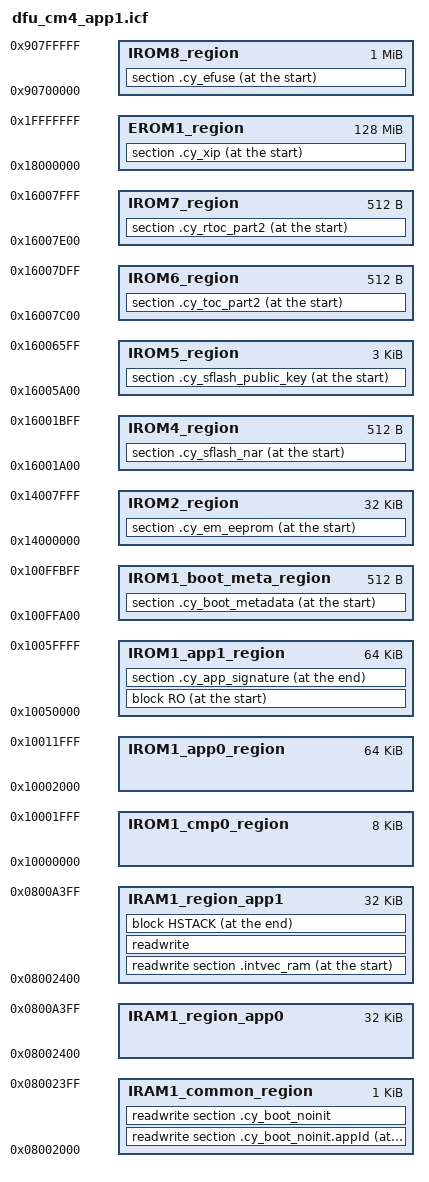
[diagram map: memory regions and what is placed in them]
/***************************************************************************//**
* \file dfu_cm4_app1.icf
* \version 5.2
*
* The linker file for the GNU C compiler.
* Used for the DFU SDK application 1 firmware project.
* Contains only CM4 sections (no section for the CM0p image that
* starts CM4 application 0). Application 1 is uploaded through
* Bootloader Host Tool using the generated cyadc2 file.
*
* \note
* This linker file is generic and handles common use cases. Your project may not
* use each section defined in the linker file and then you may see warnings
* during the build process. Simply comment out or remove the relevant code
* in the linker file.
*
********************************************************************************
* \copyright
* (c) (2016-2024), Cypress Semiconductor Corporation (an Infineon company) or
* an affiliate of Cypress Semiconductor Corporation. All rights reserved.
********************************************************************************
* This software, including source code, documentation and related materials
* ("Software") is owned by Cypress Semiconductor Corporation or one of its
* affiliates ("Cypress") and is protected by and subject to worldwide patent
* protection (United States and foreign), United States copyright laws and
* international treaty provisions. Therefore, you may use this Software only
* as provided in the license agreement accompanying the software package from
* which you obtained this Software ("EULA").
*
* If no EULA applies, Cypress hereby grants you a personal, non-exclusive,
* non-transferable license to copy, modify, and compile the Software source
* code solely for use in connection with Cypress's integrated circuit products.
* Any reproduction, modification, translation, compilation, or representation
* of this Software except as specified above is prohibited without the express
* written permission of Cypress.
*
* Disclaimer: THIS SOFTWARE IS PROVIDED AS-IS, WITH NO WARRANTY OF ANY KIND,
* EXPRESS OR IMPLIED, INCLUDING, BUT NOT LIMITED TO, NONINFRINGEMENT, IMPLIED
* WARRANTIES OF MERCHANTABILITY AND FITNESS FOR A PARTICULAR PURPOSE. Cypress
* reserves the right to make changes to the Software without notice. Cypress
* does not assume any liability arising out of the application or use of the
* Software or any product or circuit described in the Software. Cypress does
* not authorize its products for use in any products where a malfunction or
* failure of the Cypress product may reasonably be expected to result in
* significant property damage, injury or death ("High Risk Product"). By
* including Cypress's product in a High Risk Product, the manufacturer of such
* system or application assumes all risk of such use and in doing so agrees to
* indemnify Cypress against all liability.
*******************************************************************************/

/*###ICF### Section handled by ICF editor, don't touch! ****/
/*-Editor annotation file-*/
/* IcfEditorFile="$TOOLKIT_DIR$\config\ide\IcfEditor\cortex_v1_4.xml" */
/*-Specials-*/
define symbol __ICFEDIT_intvec_start__ = 0x00000000;

/* The symbols below define the location and size of blocks of memory in the target.
 * Use these symbols to specify the memory regions available for allocation.
 */

/* The following symbols control RAM and flash memory allocation for the CM4 core.
 * You can change the memory allocation by editing RAM and flash symbols.
 * Note that 2 KB of RAM (at the end of the SRAM) are reserved for system use.
 * Using this memory region for other purposes will lead to unexpected behavior.
 * Your changes must be aligned with the corresponding symbols for CM0+ core in 'xx_cm0plus.icf',
 * where 'xx' is the device group; for example, 'cy8c6xx7_cm0plus.icf'.
 */
/* RAM */
define symbol __ICFEDIT_region_IRAM1_comon_start__ = 0x08002000;
define symbol __ICFEDIT_region_IRAM1_comon_end__   = 0x080023FF;

define symbol __ICFEDIT_region_IRAM1_app0_start__ = 0x08002400;
define symbol __ICFEDIT_region_IRAM1_app0_end__   = 0x0800A3FF;

define symbol __ICFEDIT_region_IRAM1_app1_start__ = 0x08002400;
define symbol __ICFEDIT_region_IRAM1_app1_end__   = 0x0800A3FF;

/* Flash */
define symbol __ICFEDIT_region_IROM1_cm0p_start__ = 0x10000000;
define symbol __ICFEDIT_region_IROM1_cm0p_end__   = 0x10001FFF;

define symbol __ICFEDIT_region_IROM1_app0_start__ = 0x10002000;
define symbol __ICFEDIT_region_IROM1_app0_end__   = 0x10011FFF;

define symbol __ICFEDIT_region_IROM1_app1_start__ = 0x10050000;
define symbol __ICFEDIT_region_IROM1_app1_end__   = 0x1005FFFF;

/* The region for DFU SDK metadata when it is outside of any application */
define symbol __ICFEDIT_region_IROM1_boot_meta_start__ = 0x100FFA00;
define symbol __ICFEDIT_region_IROM1_boot_meta_end__   = 0x100FFBFF;

/* The following symbols define a 32K flash region used for EEPROM emulation.
 * This region can also be used as the general purpose flash.
 * You can assign sections to this memory region for only one of the cores.
 * Note some middleware (e.g. BLE, Emulated EEPROM) can place their data into this memory region.
 * Therefore, repurposing this memory region will prevent such middleware from operation.
 */
define symbol __ICFEDIT_region_IROM2_start__ = 0x14000000;
define symbol __ICFEDIT_region_IROM2_end__   = 0x14007FFF;

/* The following symbols define device specific memory regions and must not be changed. */
/* Supervisory flash - User Data */
define symbol __ICFEDIT_region_IROM3_start__ = 0x16000800;
define symbol __ICFEDIT_region_IROM3_end__   = 0x160007FF;

/* Supervisory flash - Normal Access Restrictions (NAR) */
define symbol __ICFEDIT_region_IROM4_start__ = 0x16001A00;
define symbol __ICFEDIT_region_IROM4_end__   = 0x16001BFF;

/* Supervisory flash - Public Key */
define symbol __ICFEDIT_region_IROM5_start__ = 0x16005A00;
define symbol __ICFEDIT_region_IROM5_end__   = 0x160065FF;

/* Supervisory flash - Table of Content # 2 */
define symbol __ICFEDIT_region_IROM6_start__ = 0x16007C00;
define symbol __ICFEDIT_region_IROM6_end__   = 0x16007DFF;

/* Supervisory flash - Table of Content # 2 Copy */
define symbol __ICFEDIT_region_IROM7_start__ = 0x16007E00;
define symbol __ICFEDIT_region_IROM7_end__   = 0x16007FFF;

/* eFuse */
define symbol __ICFEDIT_region_IROM8_start__ = 0x90700000;
define symbol __ICFEDIT_region_IROM8_end__   = 0x907FFFFF;

/* XIP */
define symbol __ICFEDIT_region_EROM1_start__ = 0x18000000;
define symbol __ICFEDIT_region_EROM1_end__   = 0x1FFFFFFF;

/*-Sizes-*/
if (!isdefinedsymbol(__STACK_SIZE)) {
  define symbol __ICFEDIT_size_cstack__ = 0x1000;
} else {
  define symbol __ICFEDIT_size_cstack__ = __STACK_SIZE;
}
define symbol __ICFEDIT_size_proc_stack__ = 0x0;

/* Defines the minimum heap size. The actual heap size will be expanded to the end of the stack region */
if (!isdefinedsymbol(__HEAP_SIZE)) {
    define symbol __ICFEDIT_size_heap__ = 0x0400;
} else {
  define symbol __ICFEDIT_size_heap__ = __HEAP_SIZE;
}
/**** End of ICF editor section. ###ICF###*/

/* Size of the Cortex-M0+ application image */
define symbol FLASH_CM0P_SIZE  = 0x2000;

define memory mem with size = 4G;
define region IROM1_cmp0_region = mem:[from __ICFEDIT_region_IROM1_cm0p_start__ to __ICFEDIT_region_IROM1_cm0p_end__];
define region IROM1_app0_region = mem:[from __ICFEDIT_region_IROM1_app0_start__ to __ICFEDIT_region_IROM1_app0_end__];
define region IROM1_app1_region = mem:[from __ICFEDIT_region_IROM1_app1_start__ to __ICFEDIT_region_IROM1_app1_end__];
define region IROM1_boot_meta_region  = mem:[from __ICFEDIT_region_IROM1_boot_meta_start__ to __ICFEDIT_region_IROM1_boot_meta_end__];
define region IROM2_region = mem:[from __ICFEDIT_region_IROM2_start__ to __ICFEDIT_region_IROM2_end__];
define region IROM3_region = mem:[from __ICFEDIT_region_IROM3_start__ to __ICFEDIT_region_IROM3_end__];
define region IROM4_region = mem:[from __ICFEDIT_region_IROM4_start__ to __ICFEDIT_region_IROM4_end__];
define region IROM5_region = mem:[from __ICFEDIT_region_IROM5_start__ to __ICFEDIT_region_IROM5_end__];
define region IROM6_region = mem:[from __ICFEDIT_region_IROM6_start__ to __ICFEDIT_region_IROM6_end__];
define region IROM7_region = mem:[from __ICFEDIT_region_IROM7_start__ to __ICFEDIT_region_IROM7_end__];
define region IROM8_region = mem:[from __ICFEDIT_region_IROM8_start__ to __ICFEDIT_region_IROM8_end__];
define region EROM1_region = mem:[from __ICFEDIT_region_EROM1_start__ to __ICFEDIT_region_EROM1_end__];
define region IRAM1_common_region = mem:[from __ICFEDIT_region_IRAM1_comon_start__ to __ICFEDIT_region_IRAM1_comon_end__];
define region IRAM1_region_app0   = mem:[from __ICFEDIT_region_IRAM1_app0_start__  to __ICFEDIT_region_IRAM1_app0_end__];
define region IRAM1_region_app1   = mem:[from __ICFEDIT_region_IRAM1_app1_start__  to __ICFEDIT_region_IRAM1_app1_end__];

define block CSTACK     with alignment = 8, size = __ICFEDIT_size_cstack__     { };
define block PROC_STACK with alignment = 8, size = __ICFEDIT_size_proc_stack__ { };
define block HEAP       with expanding size, alignment = 8, minimum size = __ICFEDIT_size_heap__ { };
define block HSTACK {block HEAP, block PROC_STACK, last block CSTACK};
define block RO     {first section .intvec, readonly};

/*-Initializations-*/
initialize by copy { readwrite };
do not initialize  { section .noinit, section .intvec_ram,
                     section .cy_boot_noinit.appId, section .cy_boot_noinit };

/*-Placement-*/

/* Flash - Cortex-M4 application image */
place at start of IROM1_app1_region  { block RO };
".cy_app_signature": place at end of IROM1_app1_region { section .cy_app_signature };

/* Emulated EEPROM flash area */
".cy_em_eeprom" : place at start of IROM2_region  { section .cy_em_eeprom };

/* Supervisory flash - User Data */
".cy_sflash_user_data" : place at start of IROM3_region  { section .cy_sflash_user_data };

/* Supervisory flash - NAR */
".cy_sflash_nar" : place at start of IROM4_region  { section .cy_sflash_nar };

/* Supervisory flash - Public Key */
".cy_sflash_public_key" : place at start of IROM5_region  { section .cy_sflash_public_key };

/* Supervisory flash - TOC2 */
".cy_toc_part2" : place at start of IROM6_region  { section .cy_toc_part2 };

/* Supervisory flash - RTOC2 */
".cy_rtoc_part2" : place at start of IROM7_region  { section .cy_rtoc_part2 };

/* eFuse */
".cy_efuse" : place at start of IROM8_region  { section .cy_efuse };

/* Execute in Place (XIP). See the smif driver documentation for details. */
".cy_xip" : place at start of EROM1_region  { section .cy_xip };

/* RAM */
place at start of IRAM1_common_region   { readwrite section .cy_boot_noinit.appId };
place in          IRAM1_common_region   { readwrite section .cy_boot_noinit };
place at start of IRAM1_region_app1  { readwrite section .intvec_ram};
place in          IRAM1_region_app1  { readwrite };
place at end   of IRAM1_region_app1  { block HSTACK };

/* These sections are used for additional metadata (silicon revision, Silicon/JTAG ID, etc.) storage. */
".cymeta" : place at address mem : 0x90500000 { readonly section .cymeta };

/* App0 uses it to initialize DFU SDK metadata, in the dfu_user.c file */
".cy_boot_metadata" : place at start of IROM1_boot_meta_region { section .cy_boot_metadata };

keep {  section .cy_m0p_image,
    section .cy_app_signature,
        section .cy_em_eeprom,
        section .cy_sflash_user_data,
        section .cy_sflash_nar,
        section .cy_sflash_public_key,
        section .cy_toc_part2,
        section .cy_rtoc_part2,
        section .cy_efuse,
        section .cy_xip,
        section .cymeta,
        section .cy_boot_metadata,
        section .cy_boot_noinit,
        section .cy_boot_noinit.appId,
         };


/* The following symbols used by the cymcuelftool. */
/* Flash */
define exported symbol __cy_memory_0_start    = 0x10000000;
define exported symbol __cy_memory_0_length   = 0x00100000;
define exported symbol __cy_memory_0_row_size = 0x200;

/* Emulated EEPROM flash area */
define exported symbol __cy_memory_1_start    = 0x14000000;
define exported symbol __cy_memory_1_length   = 0x8000;
define exported symbol __cy_memory_1_row_size = 0x200;

/* Supervisory flash */
define exported symbol __cy_memory_2_start    = 0x16000000;
define exported symbol __cy_memory_2_length   = 0x8000;
define exported symbol __cy_memory_2_row_size = 0x200;

/* XIP */
define exported symbol __cy_memory_3_start    = 0x18000000;
define exported symbol __cy_memory_3_length   = 0x08000000;
define exported symbol __cy_memory_3_row_size = 0x200;

/* eFuse */
define exported symbol __cy_memory_4_start    = 0x90700000;
define exported symbol __cy_memory_4_length   = 0x100000;
define exported symbol __cy_memory_4_row_size = 1;

/*******************************************************************************
* The following symbols used by the cymcuelftool and dfu sdk
*******************************************************************************/

/* Used by all DFU SDK and CyMCUElfTool */
define exported symbol __cy_boot_metadata_addr   = 0x100FFA00;
define exported symbol __cy_boot_metadata_length = __cy_memory_0_row_size;

/* Used by CyMCUElfTool to generate ProductID for DFU SDK apps */
define exported symbol __cy_product_id = 0x01020304;

/* Used by CyMCUElfTool to generate ChecksumType for DFU SDK apps */
define exported symbol __cy_checksum_type = 0;

/*
* The size of the application signature.
* E.g. 4 for CRC-32,
*     32 for SHA256,
*    256 for RSA 2048.
*/
define exported symbol __cy_boot_signature_size = 4;

/* Used by DFU SDK projects, in dfu_user.c to fill in the metadata table */
define exported symbol __cy_app0_verify_start  = start(IROM1_app0_region);
define exported symbol __cy_app0_verify_length = size (IROM1_app0_region) - __cy_boot_signature_size;

define exported symbol __cy_app1_verify_start  = start(IROM1_app1_region);
define exported symbol __cy_app1_verify_length = size (IROM1_app1_region) - __cy_boot_signature_size;

/* CyMCUElfTool uses this symbol to set a proper app number */
define exported symbol __cy_app_id = 1;

/* CyMCUElfTool uses these to generate an application signature */
/* The size of the default signature (CRC-32C) is 4 bytes */
define exported symbol __cy_app_verify_start  = start(IROM1_app1_region);
define exported symbol __cy_app_verify_length =  size(IROM1_app1_region) - __cy_boot_signature_size;

/* EOF */
